# STM32WB05 register map
File version: 1.0
CPU: CM0+ r0p0, little endian, MPU, no FPU, 2 interrupt priority bits
Registers are 32-bit, read-write, reset 0x0 unless marked. A register's access mark holds for its fields unless they carry their own. Offsets are from the block's base; [hi:lo] are bit positions.

## RRM
Base 0x60001400
0x10 UDRA_CTRL0
  [0] RELOAD_RDCFGPTR — reload the radio configuration pointer from RAM.
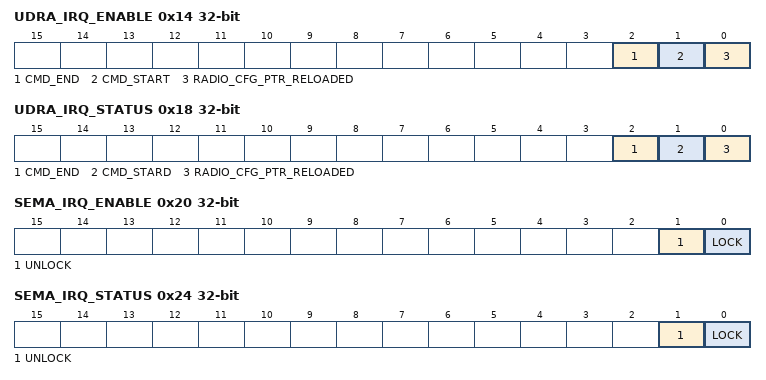
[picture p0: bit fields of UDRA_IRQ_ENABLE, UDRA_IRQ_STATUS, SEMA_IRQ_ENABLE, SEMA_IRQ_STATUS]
0x14 UDRA_IRQ_ENABLE
  [2] CMD_END — UDRA interrupt enable (command end)
  [1] CMD_START — UDRA interrupt enable (command start)
  [0] RADIO_CFG_PTR_RELOADED — UDRA interrupt enable (reload radio config pointer)
0x18 UDRA_IRQ_STATUS
  [2] CMD_END — On read, returns the UDRA command end interrupt status
  [1] CMD_STARD — On read, returns the UDRA command start interrupt status.
  [0] RADIO_CFG_PTR_RELOADED — On read, returns the UDRA reload radio configuration pointer interrupt status.
0x1C UDRA_RADIO_CFG_PTR ro
  [31:0] RADIO_CONFIG_ADDRESS — UDRA radio configuration address.
0x20 SEMA_IRQ_ENABLE
  [1] UNLOCK — semaphore unlocked (=no port selected) interrupt enable
  [0] LOCK — semaphore locked (= one port granted) interrupt enable
0x24 SEMA_IRQ_STATUS
  [1] UNLOCK — On read, returns the semaphore unlocked interrupt status.
  [0] LOCK — On read, returns the semaphore locked interrupt status.
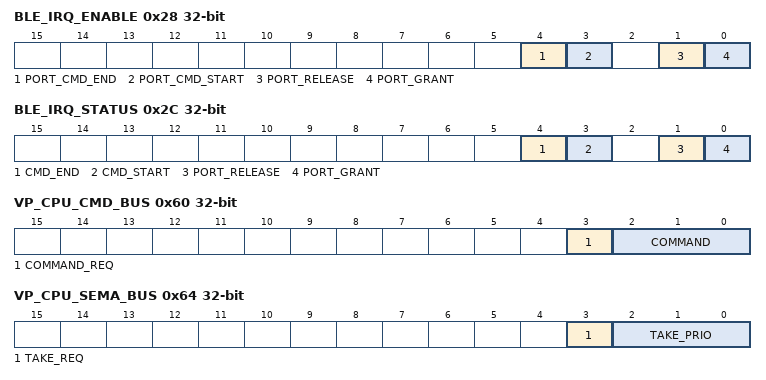
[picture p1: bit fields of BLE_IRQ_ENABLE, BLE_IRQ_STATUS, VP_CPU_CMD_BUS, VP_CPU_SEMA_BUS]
0x28 BLE_IRQ_ENABLE
  [4] PORT_CMD_END — IP_BLE Port command end interrup enable
  [3] PORT_CMD_START — IP_BLE Port command start interrup enable
  [1] PORT_RELEASE — IP_BLE Port release interrupt enable
  [0] PORT_GRANT — IP_BLE Port grant interrupt enable
0x2C BLE_IRQ_STATUS
  [4] CMD_END — IP_BLE hardware port command end interrupt status.
  [3] CMD_START — IP_BLE hardware port command start interrupt status.
  [1] PORT_RELEASE — IP_BLE hardware port released interrupt status.
  [0] PORT_GRANT — IP_BLE hardware port granted interrupt status:
0x60 VP_CPU_CMD_BUS
  [3] COMMAND_REQ — CPU Virtual port command request:
  [2:0] COMMAND — command number
0x64 VP_CPU_SEMA_BUS
  [3] TAKE_REQ — semaphore token request:
  [2:0] TAKE_PRIO — semaphore priority: priority value (between 0 and 7) of the take request.
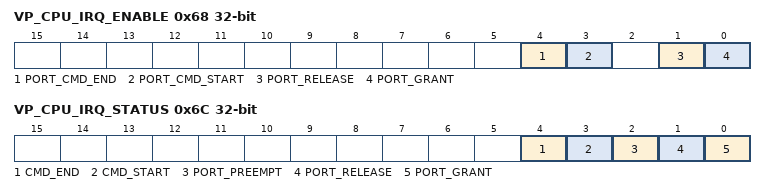
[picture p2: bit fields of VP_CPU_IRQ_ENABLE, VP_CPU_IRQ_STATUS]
0x68 VP_CPU_IRQ_ENABLE
  [4] PORT_CMD_END — CPU virtual port command end interrup enable
  [3] PORT_CMD_START — CPU virtual port command start interrup enable
  [1] PORT_RELEASE — CPU virtual port release interrupt enable
  [0] PORT_GRANT — CPU virtual port grant interrupt enable
0x6C VP_CPU_IRQ_STATUS
  [4] CMD_END — CPU virtual port command end interrupt status.
  [3] CMD_START — CPU virtual port command start interrupt status.
  [2] PORT_PREEMPT — CPU virtual port preemption (at semaphore level) interrupt status.
  [1] PORT_RELEASE — virtual port released interrupt status.
  [0] PORT_GRANT — CPU virtual port granted interrupt status.

## WAKEUP
Base 0x60001800
0x08 OFFSET — WAKEUP_OFFSET register
  [7:0] WAKEUP_OFFSET — delay of anticipation of the Soc device to settle power and clock
0x10 ABSOLUTE_TIME ro
0x14 MINIMUM_PERIOD_LENGTH ro
  [13:4] LENGTH — minimum period length computed by Time Interpolator
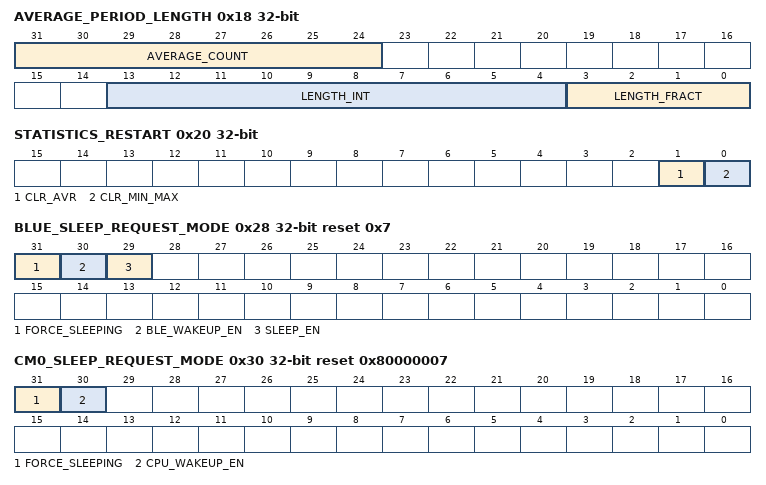
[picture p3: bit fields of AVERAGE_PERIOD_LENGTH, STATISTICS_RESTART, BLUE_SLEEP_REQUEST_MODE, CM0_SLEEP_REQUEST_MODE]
0x18 AVERAGE_PERIOD_LENGTH ro
  [31:24] AVERAGE_COUNT — Number of slow clock cycles.
  [13:4] LENGTH_INT — average period length computed by Time Interpolator.
  [3:0] LENGTH_FRACT — additional information/precision on slow clock frequency.
0x1C MAXIMUM_PERIOD_LENGTH ro
  [13:4] LENGTH — maximum period length computed by Time Interpolator
0x20 STATISTICS_RESTART
  [1] CLR_AVR — Write '1' to clear the AVERAGE_PERIOD_LENGTH register value.
  [0] CLR_MIN_MAX — Write '1' to clear the minimum and maximum registers.
0x24 BLUE_WAKEUP_TIME
  [31:0] WAKEUP_TIME — programmed wakeup time for the IP_BLE.
0x28 BLUE_SLEEP_REQUEST_MODE reset 0x7
  [31] FORCE_SLEEPING — IP_BLE sleeping control:
  [30] BLE_WAKEUP_EN — IP_BLE wakeup enable:
  [29] SLEEP_EN — IP_BLE sleeping mode enable:
0x2C CM0_WAKEUP_TIME
  [31:4] WAKEUP_TIME — programmed wakeup time for CPU.
0x30 CM0_SLEEP_REQUEST_MODE reset 0x80000007
  [31] FORCE_SLEEPING — CPU sleeping control:
  [30] CPU_WAKEUP_EN — CPU wakeup enable:
0x40 BLE_IRQ_ENABLE — WAKEUP_BLE_IRQ_ENABLE register
  [0] WAKEUP_IT — IP_BLE wakeup interrupt enable:
0x44 BLE_IRQ_STATUS — WAKEUP_BLE_IRQ_STATUS register
  [0] WAKEUP_IT — On read, returns the IP_BLE wakeup interrupt status.
0x48 CM0_IRQ_ENABLE — WAKEUP_CM0_IRQ_ENABLE register
  [0] WAKEUP_IT — CPU wakeup interrupt enable:
0x4C CM0_IRQ_STATUS — WAKEUP_CM0_IRQ_STATUS register
  [0] WAKEUP_IT — On read, returns the CPU wakeup interrupt status.
